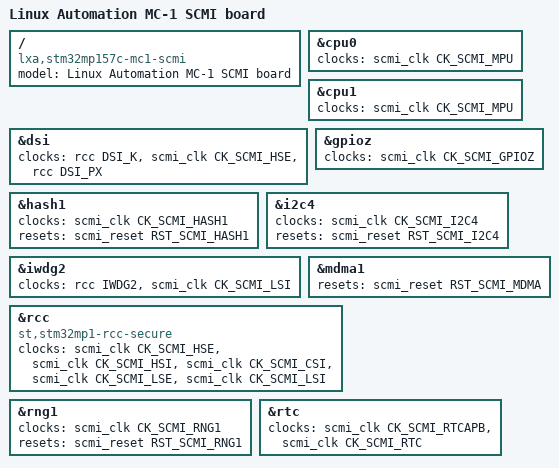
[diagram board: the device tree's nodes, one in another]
// SPDX-License-Identifier: (GPL-2.0+ OR BSD-3-Clause)
#include "stm32mp157c-lxa-mc1.dts"
#include "stm32mp1-scmi-smc.dtsi"

/ {
	model = "Linux Automation MC-1 SCMI board";
	compatible = "lxa,stm32mp157c-mc1-scmi", "lxa,stm32mp157c-mc1",
			   "oct,stm32mp15xx-osd32", "st,stm32mp157";

};

&cpu0 {
	clocks = <&scmi_clk CK_SCMI_MPU>;
};

&cpu1 {
	clocks = <&scmi_clk CK_SCMI_MPU>;
};

&dsi {
	clocks = <&rcc DSI_K>, <&scmi_clk CK_SCMI_HSE>, <&rcc DSI_PX>;
};

&gpioz {
	clocks = <&scmi_clk CK_SCMI_GPIOZ>;
};

&hash1 {
	clocks = <&scmi_clk CK_SCMI_HASH1>;
	resets = <&scmi_reset RST_SCMI_HASH1>;
};

&i2c4 {
	clocks = <&scmi_clk CK_SCMI_I2C4>;
	resets = <&scmi_reset RST_SCMI_I2C4>;
};

&iwdg2 {
	clocks = <&rcc IWDG2>, <&scmi_clk CK_SCMI_LSI>;
};

&mdma1 {
	resets = <&scmi_reset RST_SCMI_MDMA>;
};

&rcc {
	compatible = "st,stm32mp1-rcc-secure", "syscon";
	clock-names = "hse", "hsi", "csi", "lse", "lsi";
	clocks = <&scmi_clk CK_SCMI_HSE>,
		 <&scmi_clk CK_SCMI_HSI>,
		 <&scmi_clk CK_SCMI_CSI>,
		 <&scmi_clk CK_SCMI_LSE>,
		 <&scmi_clk CK_SCMI_LSI>;
};

&rng1 {
	clocks = <&scmi_clk CK_SCMI_RNG1>;
	resets = <&scmi_reset RST_SCMI_RNG1>;
};

&rtc {
	clocks = <&scmi_clk CK_SCMI_RTCAPB>, <&scmi_clk CK_SCMI_RTC>;
};
